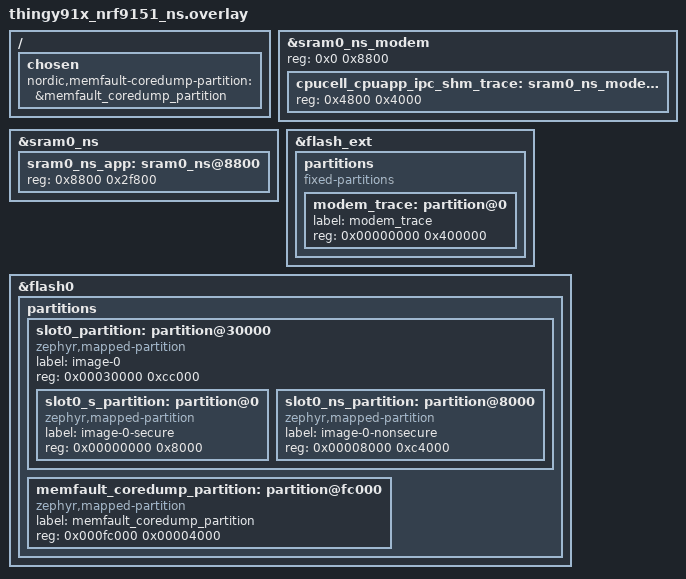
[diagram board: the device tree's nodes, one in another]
/*
 * Copyright (c) 2025 Nordic Semiconductor ASA
 *
 * SPDX-License-Identifier: LicenseRef-Nordic-5-Clause
 */

/ {
	chosen {
		nordic,memfault-coredump-partition = &memfault_coredump_partition;
	};
};

/* Increase modem (shared) memory to add trace section. */
&sram0_ns_modem {
	reg = <0x0 0x8800>;
	ranges = <0x0 0x0 0x8800>;

	cpucell_cpuapp_ipc_shm_trace: sram0_ns_modem@4800 {
		/* Modem trace memory */
		reg = <0x4800 0x4000>;
	};
};

/* Delete Non-Secure application memory so we can move and shrink it. */
/delete-node/ &sram0_ns_app;

&sram0_ns {
	sram0_ns_app: sram0_ns@8800 {
		/* Redefine smaller Non-Secure application memory. */
		reg = <0x8800 0x2f800>;
	};
};

&flash_ext {
	partitions {
		compatible = "fixed-partitions";
		#address-cells = <1>;
		#size-cells = <1>;

		modem_trace: partition@0 {
			label = "modem_trace";
			reg = <0x00000000 0x400000>;
		};
	};
};

/* The internal-flash coredump backend (CONFIG_MEMFAULT_NCS_INTERNAL_FLASH_BACKED_COREDUMP)
 * memory-maps the coredump partition and reads it with memcpy(), so it must live in
 * internal flash (not on the external flash_ext). The internal flash is fully consumed
 * by slot0_partition, so shrink the non-secure image area by 16 kB to free space for the
 * coredump partition at the end of internal flash (mirrors the memfault-coredump snippet).
 */
/delete-node/ &slot0_partition;

&flash0 {
	partitions {
		slot0_partition: partition@30000 {
			compatible = "zephyr,mapped-partition";
			label = "image-0";
			reg = <0x00030000 0xcc000>;
			ranges = <0x0 0x00030000 0xcc000>;
			#address-cells = <1>;
			#size-cells = <1>;

			slot0_s_partition: partition@0 {
				compatible = "zephyr,mapped-partition";
				label = "image-0-secure";
				reg = <0x00000000 0x8000>;
			};

			slot0_ns_partition: partition@8000 {
				compatible = "zephyr,mapped-partition";
				label = "image-0-nonsecure";
				reg = <0x00008000 0xc4000>;
			};
		};

		memfault_coredump_partition: partition@fc000 {
			compatible = "zephyr,mapped-partition";
			label = "memfault_coredump_partition";
			reg = <0x000fc000 0x00004000>;
		};
	};
};
